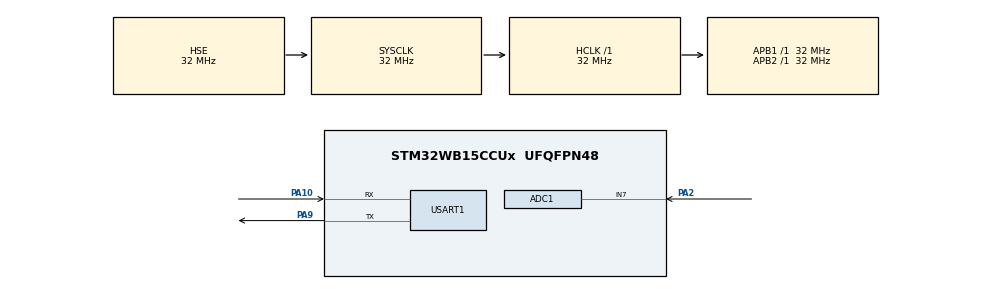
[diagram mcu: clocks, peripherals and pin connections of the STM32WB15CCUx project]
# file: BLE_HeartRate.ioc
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ADC1.Channel-2\#ChannelRegularConversion=ADC_CHANNEL_7
ADC1.NbrOfConversionFlag=1
ADC1.Rank-2\#ChannelRegularConversion=1
ADC1.SamplingTime-2\#ChannelRegularConversion=ADC_SAMPLINGTIME_COMMON_1
ADC1.SelectedChannel=ADC_CHANNEL_7
ADC1.master=1
Dma.Request0=USART1_TX
Dma.USART1_TX.0.Direction=DMA_MEMORY_TO_PERIPH
Dma.USART1_TX.0.EventEnable=DISABLE
Dma.USART1_TX.0.Instance=DMA1_Channel4
Dma.USART1_TX.0.MemDataAlignment=DMA_MDATAALIGN_BYTE
Dma.USART1_TX.0.MemInc=DMA_MINC_ENABLE
Dma.USART1_TX.0.Mode=DMA_NORMAL
Dma.USART1_TX.0.PeriphDataAlignment=DMA_PDATAALIGN_BYTE
Dma.USART1_TX.0.PeriphInc=DMA_PINC_DISABLE
Dma.USART1_TX.0.Polarity=HAL_DMAMUX_REQ_GEN_RISING
Dma.USART1_TX.0.Priority=DMA_PRIORITY_LOW
Dma.USART1_TX.0.RequestNumber=1
Dma.USART1_TX.0.SignalID=NONE
Dma.USART1_TX.0.SyncEnable=DISABLE
Dma.USART1_TX.0.SyncPolarity=HAL_DMAMUX_SYNC_NO_EVENT
Dma.USART1_TX.0.SyncRequestNumber=1
Dma.USART1_TX.0.SyncSignalID=NONE
Mcu.Family=STM32WB
Mcu.Name=STM32WB15CCUx
Mcu.Package=UFQFPN48
NVIC.DMA1_Channel4_IRQn=true\:15\:0\:true\:false\:true\:false\:true\:true
NVIC.HSEM_IRQn=true\:0\:0\:false\:false\:true\:false\:true\:true
NVIC.IPCC_C1_RX_IRQn=true\:0\:0\:false\:false\:true\:true\:true\:true
NVIC.IPCC_C1_TX_IRQn=true\:0\:0\:false\:false\:true\:true\:true\:true
NVIC.PriorityGroup=NVIC_PRIORITYGROUP_4
NVIC.RTC_WKUP_IRQn=true\:0\:0\:false\:false\:true\:true\:true\:true
NVIC.USART1_IRQn=true\:0\:0\:false\:false\:true\:true\:true\:true
OSC_IN.Mode=HSE-External-Oscillator
OSC_IN.Signal=RCC_OSC_IN
OSC_OUT.Mode=HSE-External-Oscillator
OSC_OUT.Signal=RCC_OSC_OUT
PA10.GPIO_PuPd=GPIO_PULLUP
PA10.GPIO_Speed=GPIO_SPEED_FREQ_VERY_HIGH
PA10.Mode=Asynchronous
PA10.Signal=USART1_RX
PA2.Signal=ADCx_IN7
PA9.GPIO_PuPd=GPIO_PULLUP
PA9.GPIO_Speed=GPIO_SPEED_FREQ_VERY_HIGH
PA9.Mode=Asynchronous
PA9.Signal=USART1_TX
PC14-OSC32_IN.Mode=LSE-External-Oscillator
PC14-OSC32_IN.Signal=RCC_OSC32_IN
PC15-OSC32_OUT.Mode=LSE-External-Oscillator
PC15-OSC32_OUT.Signal=RCC_OSC32_OUT
ProjectManager.HeapSize=0x400
ProjectManager.StackSize=0x1000
ProjectManager.TargetToolchain=STM32CubeIDE
RCC.AHBFreq_Value=32000000
RCC.APB1Freq_Value=32000000
RCC.APB1TimFreq_Value=32000000
RCC.APB2Freq_Value=32000000
RCC.APB2TimFreq_Value=32000000
RCC.APB3Freq_Value=16000000
RCC.CK48CLockSelection=RCC_USBCLKSOURCE_PLL
RCC.CortexFreq_Value=32000000
RCC.HCLKFreq_Value=32000000
RCC.HSE_VALUE=32000000
RCC.HSI_VALUE=16000000
RCC.LSE_Drive_Capability=RCC_LSEDRIVE_LOW
RCC.MSIClockRange=RCC_MSIRANGE_10
RCC.PLLSourceVirtual=RCC_PLLSOURCE_HSI
RCC.RFWKPClockSelection=RCC_RFWKPCLKSOURCE_LSE
RCC.RNGCLockSelection=RCC_RNGCLKSOURCE_LSE
RCC.RTCClockSelection=RCC_RTCCLKSOURCE_LSE
RCC.SMPSCLockSelectionVirtual=RCC_SMPSCLKSOURCE_HSE
RCC.SMPSDivider=4
RCC.SYSCLKFreq_VALUE=32000000
RCC.SYSCLKSource=RCC_SYSCLKSOURCE_HSE
RCC.VCOOutputFreq_Value=128000000
RF1.Mode=RF1_Activate
RF1.Signal=RF_RF1
SH.ADCx_IN7.0=ADC1_IN7,IN7-Single-Ended
STM32_WPAN.BLE_ADDR_TYPE=PUBLIC_ADDR
STM32_WPAN.BLE_DBG_APP_EN=0
STM32_WPAN.BLE_DBG_DIS_EN=1
STM32_WPAN.BLE_DBG_HRS_EN=1
STM32_WPAN.BLE_DBG_SVCCTL_EN=1
STM32_WPAN.BT_SIG_HEART_RATE_SENSOR=Enabled
STM32_WPAN.CFG_ADV_BD_ADDRESS=0x7257acd87a6c
STM32_WPAN.CFG_BLE_ATT_VALUE_ARRAY_SIZE=1290
STM32_WPAN.CFG_BLE_MAX_ADV_SET_NBR=2
STM32_WPAN.CFG_BLE_MAX_TX_POWER=6
STM32_WPAN.CFG_BLE_MIN_TX_POWER=-40
STM32_WPAN.CFG_BLE_NUM_GATT_ATTRIBUTES=30
STM32_WPAN.CFG_BLE_NUM_GATT_SERVICES=4
STM32_WPAN.CFG_DEBUGGER_SUPPORTED=0
STM32_WPAN.CFG_DEBUG_APP_TRACE=0
STM32_WPAN.CFG_DEBUG_BLE_TRACE=0
STM32_WPAN.CFG_DEBUG_TRACE_LIGHT=1
STM32_WPAN.CFG_DEBUG_TRACE_UART=hw_uart1
STM32_WPAN.CFG_HW_RESET_BY_FW=0
STM32_WPAN.CFG_HW_USART1_ENABLED=1
STM32_WPAN.CFG_LPM_STANDBY_SUPPORTED=1
STM32_WPAN.CFG_LPM_SUPPORTED=1
STM32_WPAN.CFG_LP_CONN_ADV_INTERVAL_MAX=2500
STM32_WPAN.CFG_USE_SMPS=0
STM32_WPAN.CUSTOM_P2P_SERVER=Disabled
STM32_WPAN.LOCAL_NAME=HRSTM
STM32_WPAN.LOCAL_NAME_FORMATTED=,'H','R','S','T','M'
STM32_WPAN.STATIC_RANDOM_ADDRESS=0x112233445566
USART1.OverSampling=UART_OVERSAMPLING_8
USART1.VirtualMode-Asynchronous=VM_ASYNC
VP_HSEM_VS_HSEM.Mode=HSEM_Activate
VP_IPCC_VS_IPCC.Mode=IPCC_Activate
VP_RNG_VS_RNG.Mode=RNG_Activate
VP_RTC_VS_RTC_Activate.Mode=RTC_Enabled
VP_RTC_VS_RTC_WakeUp_intern.Mode=WakeUp
VP_SEQUENCER_VS_SEQUENCER.Mode=SEQUENCER_Enabled
VP_STM32_WPAN_VS_BLE_HOST.Mode=STM32_WPAN_Enabled
VP_TINY_LPM_VS_TINY_LPM.Mode=TINY_LPM_Enabled
board=custom

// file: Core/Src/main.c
/* USER CODE BEGIN Header */
/**
  ******************************************************************************
  * @file           : main.c
  * @brief          : Main program body
  ******************************************************************************
  * @attention
  *
  * Copyright (c) 2021 STMicroelectronics.
  * All rights reserved.
  *
  * This software is licensed under terms that can be found in the LICENSE file
  * in the root directory of this software component.
  * If no LICENSE file comes with this software, it is provided AS-IS.
  *
  ******************************************************************************
  @verbatim
  ==============================================================================
                    ##### IMPORTANT NOTE #####
  ==============================================================================

  This application requests having the stm32wb1x_BLE_Stack_fw.bin binary
  flashed on the Wireless Coprocessor.
  If it is not the case, you need to use STM32CubeProgrammer to load the appropriate
  binary.

  All available binaries are located under following directory:
  /Projects/STM32_Copro_Wireless_Binaries

  Refer to UM2237 to learn how to use/install STM32CubeProgrammer.
  Refer to /Projects/STM32_Copro_Wireless_Binaries/ReleaseNote.html for the
  detailed procedure to change the Wireless Coprocessor binary.

  @endverbatim
  ******************************************************************************
  */
/* USER CODE END Header */
#include "main.h"

ADC_HandleTypeDef hadc1;

IPCC_HandleTypeDef hipcc;

RNG_HandleTypeDef hrng;

RTC_HandleTypeDef hrtc;

UART_HandleTypeDef huart1;
DMA_HandleTypeDef hdma_usart1_tx;

void SystemClock_Config(void);
void PeriphCommonClock_Config(void);
static void MX_RNG_Init(void);
static void MX_ADC1_Init(void);

int main(void)
{

  /* MCU Configuration--------------------------------------------------------*/

  /* Reset of all peripherals, Initializes the Flash interface and the Systick. */
  HAL_Init();
  /* Config code for STM32_WPAN (HSE Tuning must be done before system clock configuration) */
  MX_APPE_Config();

  /* Configure the system clock */
  SystemClock_Config();

/* Configure the peripherals common clocks */
  PeriphCommonClock_Config();

  /* IPCC initialisation */
  MX_IPCC_Init();

  /* Initialize all configured peripherals */
  MX_GPIO_Init();
  MX_DMA_Init();
  MX_RTC_Init();
  MX_USART1_UART_Init();
  MX_RNG_Init();
  MX_ADC1_Init();

  /* Init code for STM32_WPAN */
  MX_APPE_Init();

  /* Infinite loop */
  while (1)
  {
    MX_APPE_Process();

  }
}

void SystemClock_Config(void)
{
  RCC_OscInitTypeDef RCC_OscInitStruct = {0};
  RCC_ClkInitTypeDef RCC_ClkInitStruct = {0};

  /** Configure LSE Drive Capability
  */
  HAL_PWR_EnableBkUpAccess();
  __HAL_RCC_LSEDRIVE_CONFIG(RCC_LSEDRIVE_LOW);

  /** Initializes the RCC Oscillators according to the specified parameters
  * in the RCC_OscInitTypeDef structure.
  */
  RCC_OscInitStruct.OscillatorType = RCC_OSCILLATORTYPE_HSI|RCC_OSCILLATORTYPE_HSE
                              |RCC_OSCILLATORTYPE_LSE;
  RCC_OscInitStruct.HSEState = RCC_HSE_ON;
  RCC_OscInitStruct.LSEState = RCC_LSE_ON;
  RCC_OscInitStruct.HSIState = RCC_HSI_ON;
  RCC_OscInitStruct.HSICalibrationValue = RCC_HSICALIBRATION_DEFAULT;
  RCC_OscInitStruct.PLL.PLLState = RCC_PLL_NONE;
  if (HAL_RCC_OscConfig(&RCC_OscInitStruct) != HAL_OK)
  {
    Error_Handler();
  }

  /** Configure the SYSCLKSource, HCLK, PCLK1 and PCLK2 clocks dividers
  */
  RCC_ClkInitStruct.ClockType = RCC_CLOCKTYPE_HCLK4|RCC_CLOCKTYPE_HCLK2
                              |RCC_CLOCKTYPE_HCLK|RCC_CLOCKTYPE_SYSCLK
                              |RCC_CLOCKTYPE_PCLK1|RCC_CLOCKTYPE_PCLK2;
  RCC_ClkInitStruct.SYSCLKSource = RCC_SYSCLKSOURCE_HSE;
  RCC_ClkInitStruct.AHBCLKDivider = RCC_SYSCLK_DIV1;
  RCC_ClkInitStruct.APB1CLKDivider = RCC_HCLK_DIV1;
  RCC_ClkInitStruct.APB2CLKDivider = RCC_HCLK_DIV1;
  RCC_ClkInitStruct.AHBCLK2Divider = RCC_SYSCLK_DIV1;
  RCC_ClkInitStruct.AHBCLK4Divider = RCC_SYSCLK_DIV1;

  if (HAL_RCC_ClockConfig(&RCC_ClkInitStruct, FLASH_LATENCY_1) != HAL_OK)
  {
    Error_Handler();
  }
}

void PeriphCommonClock_Config(void)
{
  RCC_PeriphCLKInitTypeDef PeriphClkInitStruct = {0};

  /** Initializes the peripherals clock
  */
  PeriphClkInitStruct.PeriphClockSelection = RCC_PERIPHCLK_SMPS|RCC_PERIPHCLK_RFWAKEUP;
  PeriphClkInitStruct.RFWakeUpClockSelection = RCC_RFWKPCLKSOURCE_LSE;
  PeriphClkInitStruct.SmpsClockSelection = RCC_SMPSCLKSOURCE_HSE;
  PeriphClkInitStruct.SmpsDivSelection = RCC_SMPSCLKDIV_RANGE1;

  if (HAL_RCCEx_PeriphCLKConfig(&PeriphClkInitStruct) != HAL_OK)
  {
    Error_Handler();
  }
}

static void MX_ADC1_Init(void)
{

  ADC_ChannelConfTypeDef sConfig = {0};

  /** Common config
  */
  hadc1.Instance = ADC1;
  hadc1.Init.ClockPrescaler = ADC_CLOCK_ASYNC_DIV1;
  hadc1.Init.Resolution = ADC_RESOLUTION_12B;
  hadc1.Init.DataAlign = ADC_DATAALIGN_RIGHT;
  hadc1.Init.ScanConvMode = ADC_SCAN_DISABLE;
  hadc1.Init.EOCSelection = ADC_EOC_SINGLE_CONV;
  hadc1.Init.SamplingTimeCommon1 = ADC_SAMPLETIME_1CYCLE_5;
  hadc1.Init.SamplingTimeCommon2 = ADC_SAMPLETIME_1CYCLE_5;
  hadc1.Init.LowPowerAutoWait = DISABLE;
  hadc1.Init.ContinuousConvMode = DISABLE;
  hadc1.Init.NbrOfConversion = 1;
  hadc1.Init.DiscontinuousConvMode = DISABLE;
  hadc1.Init.ExternalTrigConv = ADC_SOFTWARE_START;
  hadc1.Init.ExternalTrigConvEdge = ADC_EXTERNALTRIGCONVEDGE_NONE;
  hadc1.Init.DMAContinuousRequests = DISABLE;
  hadc1.Init.Overrun = ADC_OVR_DATA_PRESERVED;
  if (HAL_ADC_Init(&hadc1) != HAL_OK)
  {
    Error_Handler();
  }

  /** Configure Regular Channel
  */
  sConfig.Channel = ADC_CHANNEL_7;
  sConfig.Rank = ADC_REGULAR_RANK_1;
  sConfig.SamplingTime = ADC_SAMPLINGTIME_COMMON_1;
  if (HAL_ADC_ConfigChannel(&hadc1, &sConfig) != HAL_OK)
  {
    Error_Handler();
  }

}

void MX_IPCC_Init(void)
{

  hipcc.Instance = IPCC;
  if (HAL_IPCC_Init(&hipcc) != HAL_OK)
  {
    Error_Handler();
  }

}

static void MX_RNG_Init(void)
{

  hrng.Instance = RNG;
  hrng.Init.ClockErrorDetection = RNG_CED_ENABLE;
  if (HAL_RNG_Init(&hrng) != HAL_OK)
  {
    Error_Handler();
  }

}

void MX_RTC_Init(void)
{

  /** Initialize RTC Only
  */
  hrtc.Instance = RTC;
  hrtc.Init.HourFormat = RTC_HOURFORMAT_24;
  hrtc.Init.AsynchPrediv = CFG_RTC_ASYNCH_PRESCALER;
  hrtc.Init.SynchPrediv = CFG_RTC_SYNCH_PRESCALER;
  hrtc.Init.OutPut = RTC_OUTPUT_DISABLE;
  hrtc.Init.OutPutPolarity = RTC_OUTPUT_POLARITY_HIGH;
  hrtc.Init.OutPutRemap = RTC_OUTPUT_REMAP_NONE;
  if (HAL_RTC_Init(&hrtc) != HAL_OK)
  {
    Error_Handler();
  }

  /** Enable the WakeUp
  */
  if (HAL_RTCEx_SetWakeUpTimer_IT(&hrtc, 0, RTC_WAKEUPCLOCK_RTCCLK_DIV16) != HAL_OK)
  {
    Error_Handler();
  }
  /* USER CODE BEGIN RTC_Init 2 */
  /* Disable RTC registers write protection */
  LL_RTC_DisableWriteProtection(RTC);

  LL_RTC_WAKEUP_SetClock(RTC, CFG_RTC_WUCKSEL_DIVIDER);

  /* Enable RTC registers write protection */
  LL_RTC_EnableWriteProtection(RTC);
  /* USER CODE END RTC_Init 2 */

}

void MX_USART1_UART_Init(void)
{

  huart1.Instance = USART1;
  huart1.Init.BaudRate = 115200;
  huart1.Init.WordLength = UART_WORDLENGTH_8B;
  huart1.Init.StopBits = UART_STOPBITS_1;
  huart1.Init.Parity = UART_PARITY_NONE;
  huart1.Init.Mode = UART_MODE_TX_RX;
  huart1.Init.HwFlowCtl = UART_HWCONTROL_NONE;
  huart1.Init.OverSampling = UART_OVERSAMPLING_8;
  huart1.Init.OneBitSampling = UART_ONE_BIT_SAMPLE_DISABLE;
  huart1.Init.ClockPrescaler = UART_PRESCALER_DIV1;
  huart1.AdvancedInit.AdvFeatureInit = UART_ADVFEATURE_NO_INIT;
  if (HAL_UART_Init(&huart1) != HAL_OK)
  {
    Error_Handler();
  }
  if (HAL_UARTEx_SetTxFifoThreshold(&huart1, UART_TXFIFO_THRESHOLD_1_8) != HAL_OK)
  {
    Error_Handler();
  }
  if (HAL_UARTEx_SetRxFifoThreshold(&huart1, UART_RXFIFO_THRESHOLD_1_8) != HAL_OK)
  {
    Error_Handler();
  }
  if (HAL_UARTEx_DisableFifoMode(&huart1) != HAL_OK)
  {
    Error_Handler();
  }

}

void MX_DMA_Init(void)
{

  /* DMA controller clock enable */
  __HAL_RCC_DMAMUX1_CLK_ENABLE();
  __HAL_RCC_DMA1_CLK_ENABLE();

  /* DMA interrupt init */
  /* DMA1_Channel4_IRQn interrupt configuration */
  HAL_NVIC_SetPriority(DMA1_Channel4_IRQn, 15, 0);
  HAL_NVIC_EnableIRQ(DMA1_Channel4_IRQn);

}

void MX_GPIO_Init(void)
{

  /* GPIO Ports Clock Enable */
  __HAL_RCC_GPIOC_CLK_ENABLE();
  __HAL_RCC_GPIOA_CLK_ENABLE();

}

void Error_Handler(void)
{
}
